VERSION ""

NS_ :

BS_:

BU_: XXX

BO_ 276 NEW_MSG_1: 8 XXX

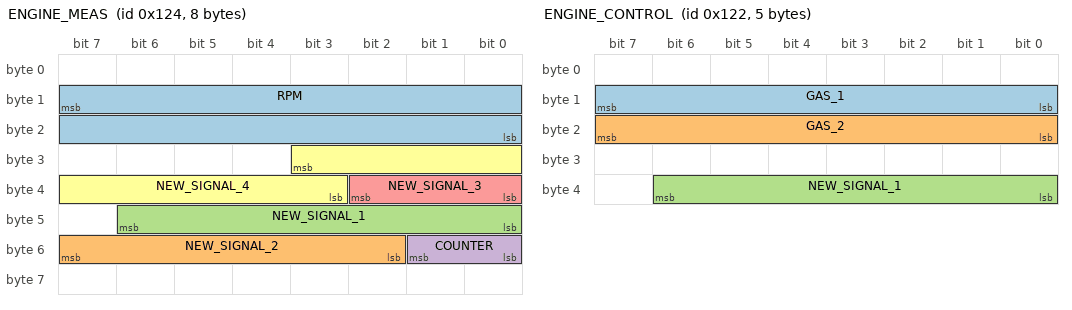
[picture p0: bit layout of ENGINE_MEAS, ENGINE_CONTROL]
BO_ 292 ENGINE_MEAS: 8 XXX
 SG_ RPM : 15|16@0+ (1,0) [0|6000] "" XXX
 SG_ NEW_SIGNAL_2 : 55|6@0+ (1,0) [0|63] "" XXX
 SG_ NEW_SIGNAL_1 : 46|7@0+ (1,0) [0|127] "" XXX
 SG_ COUNTER : 48|2@1+ (1,0) [0|3] "" XXX
 SG_ NEW_SIGNAL_3 : 34|3@0+ (1,0) [0|255] "" XXX
 SG_ NEW_SIGNAL_4 : 27|9@0+ (1,0) [0|7] "" XXX

BO_ 288 ENGINE_1: 6 XXX
 SG_ NEW_SIGNAL_1 : 11|12@0+ (1,0) [0|255] "" XXX
 SG_ NEW_SIGNAL_2 : 27|12@0+ (1,0) [0|15] "" XXX

BO_ 290 ENGINE_CONTROL: 5 XXX
 SG_ GAS_1 : 15|8@0+ (1,0) [0|255] "" XXX
 SG_ GAS_2 : 23|8@0+ (1,0) [0|255] "" XXX
 SG_ NEW_SIGNAL_1 : 38|7@0+ (1,0) [0|127] "" XXX

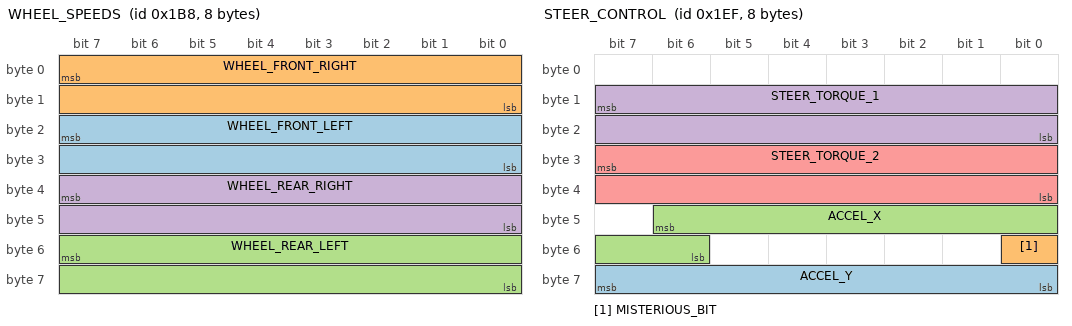
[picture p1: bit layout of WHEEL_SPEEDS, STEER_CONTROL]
BO_ 440 WHEEL_SPEEDS: 8 XXX
 SG_ WHEEL_FRONT_LEFT : 23|16@0+ (1,0) [0|511] "" XXX
 SG_ WHEEL_FRONT_RIGHT : 7|16@0+ (1,0) [0|65535] "" XXX
 SG_ WHEEL_REAR_LEFT : 55|16@0+ (1,0) [0|65535] "" XXX
 SG_ WHEEL_REAR_RIGHT : 39|16@0+ (1,0) [0|65535] "" XXX

BO_ 319 ENGINE_RPM: 8 XXX
 SG_ rpm : 13|14@0+ (0.23,0) [0|6000] "/min" XXX

BO_ 495 STEER_CONTROL: 8 XXX
 SG_ ACCEL_Y : 63|8@0- (200,0) [0|255] "" XXX
 SG_ MISTERIOUS_BIT : 48|1@1+ (1,0) [0|3] "" XXX
 SG_ ACCEL_X : 46|9@0+ (1,0) [0|8191] "" XXX
 SG_ STEER_TORQUE_1 : 15|16@0+ (0.045,0) [0|2000] "" XXX
 SG_ STEER_TORQUE_2 : 31|16@0+ (0.045,0) [0|2000] "" XXX

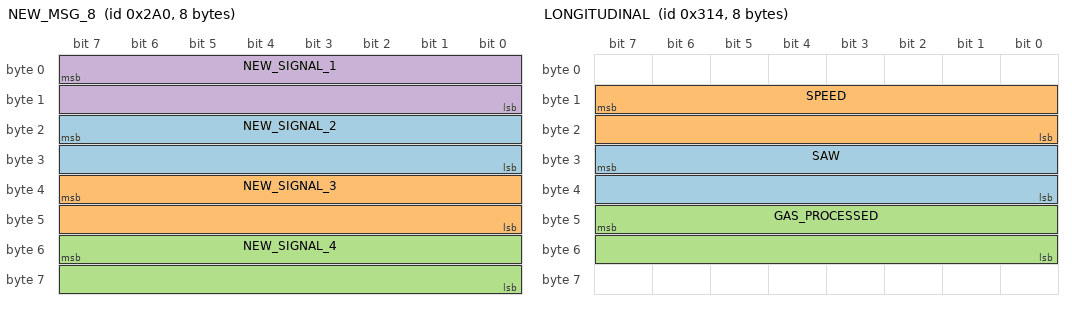
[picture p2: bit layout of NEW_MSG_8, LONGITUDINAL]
BO_ 672 NEW_MSG_8: 8 XXX
 SG_ NEW_SIGNAL_2 : 23|16@0+ (1,0) [0|65535] "" XXX
 SG_ NEW_SIGNAL_3 : 39|16@0+ (1,0) [0|65535] "" XXX
 SG_ NEW_SIGNAL_4 : 55|16@0+ (1,0) [0|65535] "" XXX
 SG_ NEW_SIGNAL_1 : 7|16@0+ (1,0) [0|255] "" XXX

BO_ 788 LONGITUDINAL: 8 XXX
 SG_ SAW : 31|16@0+ (1,0) [0|65535] "" XXX
 SG_ SPEED : 15|16@0+ (1,0) [0|65535] "" XXX
 SG_ GAS_PROCESSED : 47|16@0+ (1,0) [0|65535] "" XXX

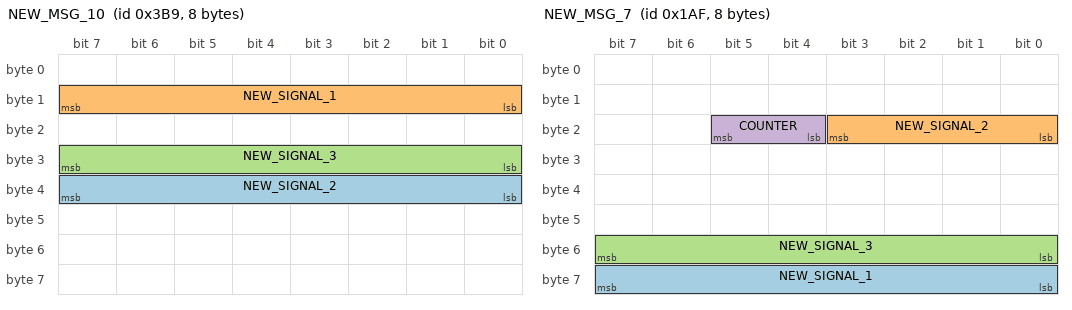
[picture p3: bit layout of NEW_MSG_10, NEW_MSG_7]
BO_ 953 NEW_MSG_10: 8 XXX
 SG_ NEW_SIGNAL_2 : 39|8@0+ (1,0) [0|255] "" XXX
 SG_ NEW_SIGNAL_1 : 15|8@0+ (1,0) [0|255] "" XXX
 SG_ NEW_SIGNAL_3 : 31|8@0+ (1,0) [0|255] "" XXX

BO_ 431 NEW_MSG_7: 8 XXX
 SG_ NEW_SIGNAL_1 : 63|8@0+ (1,0) [0|255] "" XXX
 SG_ NEW_SIGNAL_2 : 16|4@1+ (1,0) [0|15] "" XXX
 SG_ NEW_SIGNAL_3 : 55|8@0+ (1,0) [0|255] "" XXX
 SG_ COUNTER : 21|2@0+ (1,0) [0|3] "" XXX

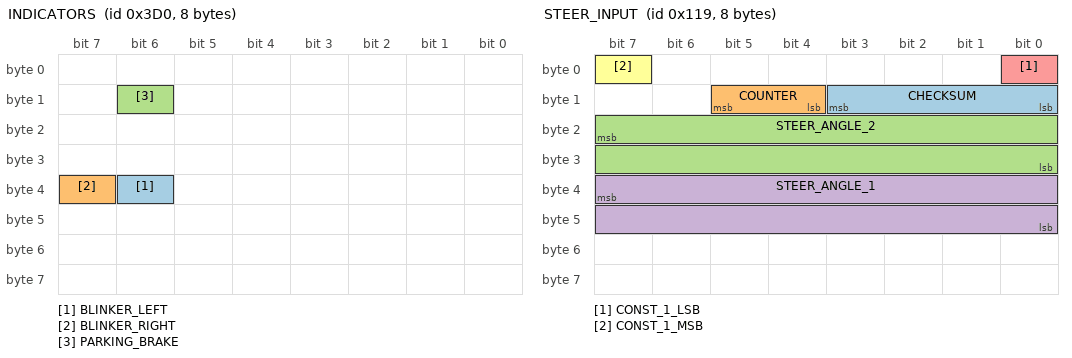
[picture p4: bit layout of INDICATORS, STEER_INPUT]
BO_ 976 INDICATORS: 8 XXX
 SG_ BLINKER_LEFT : 38|1@0+ (1,0) [0|1] "" XXX
 SG_ BLINKER_RIGHT : 39|1@0+ (1,0) [0|1] "" XXX
 SG_ PARKING_BRAKE : 14|1@0+ (1,0) [0|1] "" XXX

BO_ 977 NEW_MSG_11: 8 XXX
 SG_ DOOR_LEFT : 0|1@1+ (1,0) [0|3] "" XXX
 SG_ NEW_SIGNAL_1 : 55|16@0+ (1,0) [0|255] "" XXX

BO_ 792 NEW_MSG_12: 8 XXX
 SG_ NEW_SIGNAL_1 : 31|16@0- (1,0) [0|65535] "" XXX

BO_ 429 ACCEL: 8 XXX
 SG_ LATERAL : 35|8@0+ (1,0) [0|15] "" XXX

BO_ 281 STEER_INPUT: 8 XXX
 SG_ CHECKSUM : 8|4@1+ (1,0) [0|15] "" XXX
 SG_ COUNTER : 13|2@0+ (1,0) [0|3] "" XXX
 SG_ STEER_ANGLE_2 : 23|16@0+ (0.045,0) [0|2000] "deg" XXX
 SG_ STEER_ANGLE_1 : 39|16@0+ (0.045,0) [0|2000] "deg" XXX
 SG_ CONST_1_LSB : 0|1@1+ (1,0) [0|1] "" XXX
 SG_ CONST_1_MSB : 7|1@0+ (1,0) [0|1] "" XXX

BO_ 784 NEW_MSG_15: 8 XXX
 SG_ NEW_SIGNAL_1 : 15|8@0+ (1,0) [0|255] "" XXX

BO_ 1280 NEW_MSG_16: 8 XXX

BO_ 1281 NEW_MSG_17: 8 XXX

BO_ 1000 NEW_MSG_6: 8 XXX
 SG_ NEW_SIGNAL_1 : 15|8@0+ (1,0) [0|255] "" XXX
